# RZN2L register map
Vendor: Renesas Electronics Corporation; Series: RZN; File version: 1.30.01
CPU: other r0p0, little endian, MPU, no FPU, VTOR, 4 interrupt priority bits, 624 interrupts
Registers are 32-bit, read-write, reset 0x0 unless marked. A register's access mark holds for its fields unless they carry their own. Offsets are from the block's base; [hi:lo] are bit positions; {n}, {i} and the like mark numbered series; 'fields as' and 'values as' point back to an identical list.

## DMAC0 — DMA Controller 0
Base 0x80080000
Same registers: DMAC1 0x80081000
{0x0+0x40*i} N0SA_{i} (i=0..7) — Next0 Source Address Register {i}
{0x4+0x40*i} N0DA_{i} (i=0..7) — Next0 Destination Address Register {i}
{0x8+0x40*i} N0TB_{i} (i=0..7) — Next0 Transaction Byte Register {i}
{0xC+0x40*i} N1SA_{i} (i=0..7) — Next1 Source Address Register {i}
{0x10+0x40*i} N1DA_{i} (i=0..7) — Next1 Destination Address Register {i}
{0x14+0x40*i} N1TB_{i} (i=0..7) — Next1 Transaction Byte Register {i}
{0x18+0x40*i} CRSA_{i} (i=0..7) ro — Current Source Address Register {i}
{0x1C+0x40*i} CRDA_{i} (i=0..7) ro — Current Destination Address Register {i}
{0x20+0x40*i} CRTB_{i} (i=0..7) ro — Current Transaction Byte Register {i}
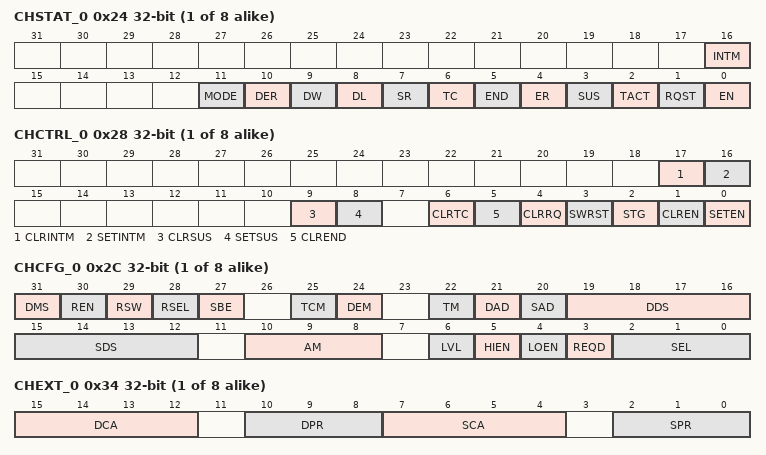
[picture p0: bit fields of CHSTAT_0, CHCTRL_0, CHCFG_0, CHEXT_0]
{0x24+0x40*i} CHSTAT_{i} (i=0..7) ro — Channel Status Register {i}
  [16] INTM — DMA Transfer Completion Interrupt Request Mask
    0=The temporary mask status is cleared; 1=Temporary mask status
  [11] MODE — DMA Mode
    0=Register mode; 1=Link mode
  [10] DER — Descriptor Error
    0=No descriptor error occurred; 1=Descriptor error occurred
  [9] DW — Descriptor Write Back
    0=Header is not written back in link mode; 1=The ER bit in the CHSTAT_n register = 0 Header is written back in link mode The ER bit in the CHSTAT_n register = 1 A bus error occurred when header is written back in link mode
  [8] DL — Descriptor Load
    0=The descriptor is not being read; 1=When ER = 0 The descriptor is being read in link mode When ER = 1 A bus error occurred while the descriptor is being read in link mode
  [7] SR — Next Register Select
    0=Next0 register set; 1=Next1 register set
  [6] TC — DMA Transfer Completion (total number of data bytes for transaction)
    0=DMA transfer not completed; 1=DMA transfer completed
  [5] END — DMA Transfer Completion Interrupt
    0=DMA transfer not completed; 1=DMA transfer completed
  [4] ER — DMA Error
    0=No bus error occurred; 1=A bus error occurred
  [3] SUS — Suspend
    0=Channel_n not suspended; 1=Channel_n suspended
  [2] TACT — DMAC Operating Status
    0=DMA in Channel_n stops; 1=DMA in Channel_n is running
  [1] RQST — DMA Transfer Request
    0=DMA transfer request not accepted; 1=DMA transfer request accepted
  [0] EN — DMA Activation Enable
    0=Operation disabled; 1=Operation enabled
{0x28+0x40*i} CHCTRL_{i} (i=0..7) — Channel Control Register {i}
  [17] CLRINTM — DMA Transfer Completion Interrupt Request Mask Clear
    0=Operation is not affected; 1=Clear the mask state set with the SETINTM bit
  [16] SETINTM — DMA Transfer Completion Interrupt Request Mask
    0=Operation is not affected; 1=Mask a DMA transfer completion interrupt temporarily
  [9] CLRSUS — Suspend Clear
    0=Operation is not affected; 1=Clear the temporary suspend status of the current DMA transfer
  [8] SETSUS — Suspend Request
    0=Operation is not affected; 1=Suspends the current DMA transfer
  [6] CLRTC — TC Clear
    0=Operation is not affected; 1=Clear the TC bit in the CHSTAT_n register
  [5] CLREND — END Clear
    0=Operation is not affected; 1=Clear the END bit
  [4] CLRRQ — DMA Transfer Request Clear
    0=Operation is not affected; 1=Clear the RQST bit in the CHSTAT_n register
  [3] SWRST — Software Reset
    0=Operation is not affected; 1=Clear each bit in the CHSTAT_n register
  [2] STG — Software Trigger
    0=Operation is not affected; 1=A transfer request is set by software (the RQST bit in the CHSTAT_n register is set)
  [1] CLREN — DMA Activation Enable Clear
    0=Operation is not affected; 1=DMA transfer is disabled (the EN bit in the CHSTAT_n register is cleared)
  [0] SETEN — DMA Activation Enable
    0=Operation is not affected; 1=DMA transfer is enabled (the EN bit in the CHSTAT_n register is set)
{0x2C+0x40*i} CHCFG_{i} (i=0..7) — Channel Configuration Register {i}
  [31] DMS — DMA Mode Select
    0=Register mode (a value after reset); 1=Link mode
  [30] REN — Register Set Enable
    0=Does not perform DMA transfer accordingly; 1=Performs DMA transfer accordingly
  [29] RSW — RSEL Reverse
    0=Does not reverse the RSEL bit when DMA transfer completes (a value after reset); 1=Reverse the RSEL bit when DMA transfer completes
  [28] RSEL — Next Register Select
    0=Execute Next0 Register Set (a value after reset); 1=Execute Next1 Register Set
  [27] SBE — Buffer Flush Enable
    0=Stop transfer without flushing data in the buffer (a value after reset); 1=Stop transfer after flushing data in the buffer
  [25] TCM — TEND Mask
    0=Does not mask (a value after reset); 1=Mask
  [24] DEM — DMA Transfer Completion Interrupt Mask
    0=Does not mask (a value after reset); 1=Mask
  [22] TM — Transfer Mode
    0=Single transfer mode (a value after reset); 1=Block transfer mode
  [21] DAD — Destination Address Count Direction
    0=Increment (a value after reset); 1=Fixed
  [20] SAD — Source Address Count Direction
    0=Increment (a value after reset); 1=Fixed
  [19:16] DDS — Destination Data Size
    0=8 bits (a value after reset); 1=16 bits; 2=32 bits; 3=64 bits; 4=128 bits; 5=256 bits; 6=512 bits (can be set only for DMAC0); other=Others (Setting prohibited)
  [15:12] SDS — Source Data Size
    values as DDS
  [10:8] AM — ACK Mode
    0=Setting is prohibited (a value after reset). At the initial setup, set a value other than 000b.; 1=Level mode (active until DMA transfer request input becomes inactive); 0b01x=Bus cycle mode (active between DMA transfer cycles (active if internal resources are the target)); 0b1xx=Mask DACK output
  [6] LVL — Level Detection Enable
    0=Detects the edge (a value after reset); 1=Detects the level
  [5] HIEN — H Detection Enable
  [4] LOEN — L Detection Enable
  [3] REQD — DMA Activation Request Source Select
    0=Requested by a transfer source module. DACK output is activated when it is read (a value after a reset).; 1=Requested by a transfer destination module. DACK output is activated when it is written.
  [2:0] SEL — Pin Select
    {v}=Channel {v} (v=0..7)
{0x30+0x40*i} CHITVL_{i} (i=0..7) — Channel Interval Register {i}
  [15:0] ITVL — Interval
{0x34+0x40*i} CHEXT_{i} (i=0..7) — Channel Extension Register {i}
  [15:12] DCA — Destination CACHE
  [10:8] DPR — Destination PROT
  [7:4] SCA — Source CACHE
  [2:0] SPR — Source PROT
{0x38+0x40*i} NXLA_{i} (i=0..7) — Next Link Address Register {i}
{0x3C+0x40*i} CRLA_{i} (i=0..7) ro — Current Link Address Register {i}
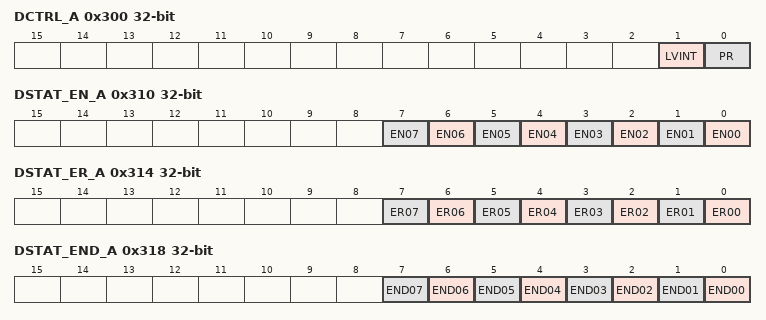
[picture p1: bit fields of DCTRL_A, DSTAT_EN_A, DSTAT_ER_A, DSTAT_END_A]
0x300 DCTRL_A — DMA Control Register A
  [1] LVINT — Sets the interrupt output mode.
    0=Pulse output; 1=Level output
  [0] PR — Priority Control Select
    0=Fixed priority mode; 1=Round-robin mode
0x310 DSTAT_EN_A ro — DMA Status EN Register A
  [n] EN{n:02} (n=0..7) — Channel {n} EN
0x314 DSTAT_ER_A ro — DMA Status ER Register A
  [n] ER{n:02} (n=0..7) — Channel {n} ER
0x318 DSTAT_END_A ro — DMA Status END Register A
  [n] END{n:02} (n=0..7) — Channel {n} END
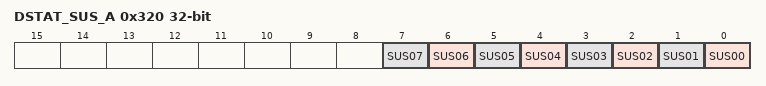
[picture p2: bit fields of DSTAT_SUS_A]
0x320 DSTAT_SUS_A ro — DMA Status SUS Register A
  [n] SUS{n:02} (n=0..7) — Channel {n} SUS

## Notices in the file
Copyright (c) 2020 - 2025 Renesas Electronics Corporation and/or its affiliates
SPDX-License-Identifier: BSD-3-Clause
